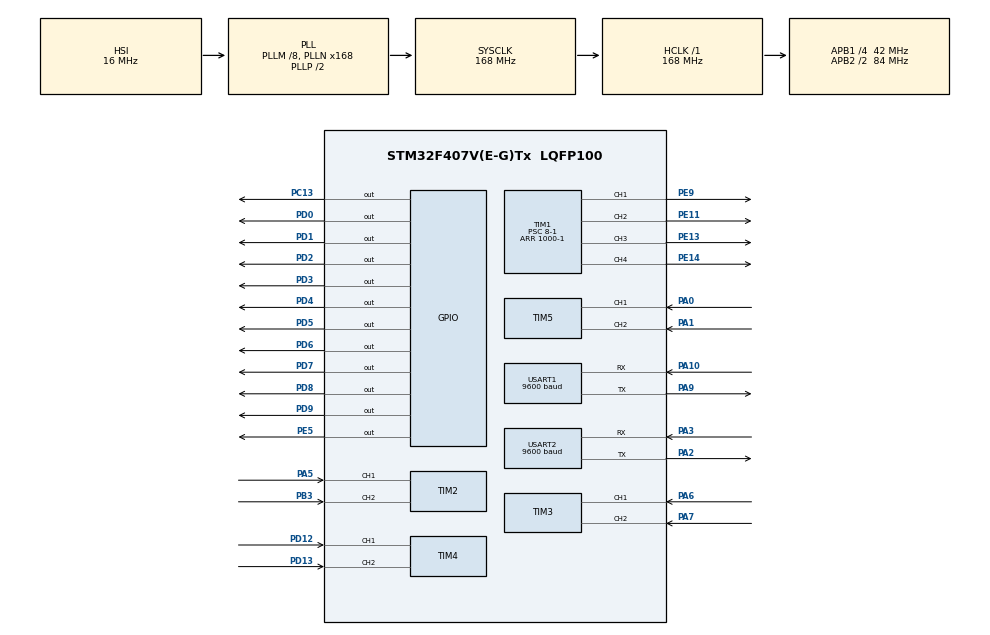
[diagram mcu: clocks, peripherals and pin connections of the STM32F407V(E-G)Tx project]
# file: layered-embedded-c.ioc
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Dma.Request0=USART1_RX
Dma.Request1=USART1_TX
Dma.Request2=USART2_RX
Dma.Request3=USART2_TX
Dma.USART1_RX.0.Direction=DMA_PERIPH_TO_MEMORY
Dma.USART1_RX.0.FIFOMode=DMA_FIFOMODE_DISABLE
Dma.USART1_RX.0.Instance=DMA2_Stream2
Dma.USART1_RX.0.MemDataAlignment=DMA_MDATAALIGN_BYTE
Dma.USART1_RX.0.MemInc=DMA_MINC_ENABLE
Dma.USART1_RX.0.Mode=DMA_CIRCULAR
Dma.USART1_RX.0.PeriphDataAlignment=DMA_PDATAALIGN_BYTE
Dma.USART1_RX.0.PeriphInc=DMA_PINC_DISABLE
Dma.USART1_RX.0.Priority=DMA_PRIORITY_LOW
Dma.USART1_TX.1.Direction=DMA_MEMORY_TO_PERIPH
Dma.USART1_TX.1.FIFOMode=DMA_FIFOMODE_DISABLE
Dma.USART1_TX.1.Instance=DMA2_Stream7
Dma.USART1_TX.1.MemDataAlignment=DMA_MDATAALIGN_BYTE
Dma.USART1_TX.1.MemInc=DMA_MINC_ENABLE
Dma.USART1_TX.1.Mode=DMA_NORMAL
Dma.USART1_TX.1.PeriphDataAlignment=DMA_PDATAALIGN_BYTE
Dma.USART1_TX.1.PeriphInc=DMA_PINC_DISABLE
Dma.USART1_TX.1.Priority=DMA_PRIORITY_LOW
Dma.USART2_RX.2.Direction=DMA_PERIPH_TO_MEMORY
Dma.USART2_RX.2.FIFOMode=DMA_FIFOMODE_DISABLE
Dma.USART2_RX.2.Instance=DMA1_Stream5
Dma.USART2_RX.2.MemDataAlignment=DMA_MDATAALIGN_BYTE
Dma.USART2_RX.2.MemInc=DMA_MINC_ENABLE
Dma.USART2_RX.2.Mode=DMA_CIRCULAR
Dma.USART2_RX.2.PeriphDataAlignment=DMA_PDATAALIGN_BYTE
Dma.USART2_RX.2.PeriphInc=DMA_PINC_DISABLE
Dma.USART2_RX.2.Priority=DMA_PRIORITY_LOW
Dma.USART2_TX.3.Direction=DMA_MEMORY_TO_PERIPH
Dma.USART2_TX.3.FIFOMode=DMA_FIFOMODE_DISABLE
Dma.USART2_TX.3.Instance=DMA1_Stream6
Dma.USART2_TX.3.MemDataAlignment=DMA_MDATAALIGN_BYTE
Dma.USART2_TX.3.MemInc=DMA_MINC_ENABLE
Dma.USART2_TX.3.Mode=DMA_NORMAL
Dma.USART2_TX.3.PeriphDataAlignment=DMA_PDATAALIGN_BYTE
Dma.USART2_TX.3.PeriphInc=DMA_PINC_DISABLE
Dma.USART2_TX.3.Priority=DMA_PRIORITY_LOW
FREERTOS.Tasks01=defaultTask,24,128,StartDefaultTask,Default,NULL,Dynamic,NULL,NULL;MonitorTask,8,512,RTOS_Monitor_StartTask,As weak,NULL,Dynamic,NULL,NULL;ControlTask,48,1024,RTOS_Control_StartTask,As weak,NULL,Dynamic,NULL,NULL;UARTTask,24,1024,RTOS_UART_StartTask,As weak,NULL,Dynamic,NULL,NULL
Mcu.Family=STM32F4
Mcu.Name=STM32F407V(E-G)Tx
Mcu.Package=LQFP100
NVIC.DMA1_Stream5_IRQn=true\:5\:0\:false\:false\:true\:true\:false\:true\:true
NVIC.DMA1_Stream6_IRQn=true\:5\:0\:false\:false\:true\:true\:false\:true\:true
NVIC.DMA2_Stream2_IRQn=true\:5\:0\:false\:false\:true\:true\:false\:true\:true
NVIC.DMA2_Stream7_IRQn=true\:5\:0\:false\:false\:true\:true\:false\:true\:true
NVIC.PriorityGroup=NVIC_PRIORITYGROUP_4
NVIC.TIM7_IRQn=true\:15\:0\:false\:false\:true\:false\:false\:true\:true
NVIC.TimeBase=TIM7_IRQn
NVIC.TimeBaseIP=TIM7
NVIC.USART1_IRQn=true\:5\:0\:false\:false\:true\:true\:true\:true\:true
PA0-WKUP.Signal=S_TIM5_CH1
PA1.Signal=S_TIM5_CH2
PA10.Mode=Asynchronous
PA10.Signal=USART1_RX
PA13.Mode=Serial_Wire
PA13.Signal=SYS_JTMS-SWDIO
PA14.Mode=Serial_Wire
PA14.Signal=SYS_JTCK-SWCLK
PA2.Mode=Asynchronous
PA2.Signal=USART2_TX
PA3.Mode=Asynchronous
PA3.Signal=USART2_RX
PA5.Signal=S_TIM2_CH1_ETR
PA6.Signal=S_TIM3_CH1
PA7.Signal=S_TIM3_CH2
PA9.Mode=Asynchronous
PA9.Signal=USART1_TX
PB3.Signal=S_TIM2_CH2
PC13-ANTI_TAMP.Signal=GPIO_Output
PD0.Signal=GPIO_Output
PD1.Signal=GPIO_Output
PD12.Signal=S_TIM4_CH1
PD13.Signal=S_TIM4_CH2
PD2.Signal=GPIO_Output
PD3.Signal=GPIO_Output
PD4.Signal=GPIO_Output
PD5.Signal=GPIO_Output
PD6.Signal=GPIO_Output
PD7.Signal=GPIO_Output
PD8.Signal=GPIO_Output
PD9.Signal=GPIO_Output
PE11.Signal=S_TIM1_CH2
PE13.Signal=S_TIM1_CH3
PE14.Signal=S_TIM1_CH4
PE5.Signal=GPIO_Output
PE9.Signal=S_TIM1_CH1
PH0-OSC_IN.Mode=HSE-External-Oscillator
PH0-OSC_IN.Signal=RCC_OSC_IN
PH1-OSC_OUT.Mode=HSE-External-Oscillator
PH1-OSC_OUT.Signal=RCC_OSC_OUT
ProjectManager.HeapSize=0x200
ProjectManager.StackSize=0x400
ProjectManager.TargetToolchain=CMake
RCC.48MHZClocksFreq_Value=84000000
RCC.AHBFreq_Value=168000000
RCC.APB1CLKDivider=RCC_HCLK_DIV4
RCC.APB1Freq_Value=42000000
RCC.APB1TimFreq_Value=84000000
RCC.APB2CLKDivider=RCC_HCLK_DIV2
RCC.APB2Freq_Value=84000000
RCC.APB2TimFreq_Value=168000000
RCC.CortexFreq_Value=168000000
RCC.HCLKFreq_Value=168000000
RCC.HSE_VALUE=25000000
RCC.HSI_VALUE=16000000
RCC.LSE_VALUE=32768
RCC.PLLM=8
RCC.PLLN=168
RCC.SYSCLKFreq_VALUE=168000000
RCC.SYSCLKSource=RCC_SYSCLKSOURCE_PLLCLK
RCC.VCOOutputFreq_Value=336000000
SH.S_TIM1_CH1.0=TIM1_CH1,PWM Generation1 CH1
SH.S_TIM1_CH2.0=TIM1_CH2,PWM Generation2 CH2
SH.S_TIM1_CH3.0=TIM1_CH3,PWM Generation3 CH3
SH.S_TIM1_CH4.0=TIM1_CH4,PWM Generation4 CH4
SH.S_TIM2_CH1_ETR.0=TIM2_CH1,Encoder_Interface
SH.S_TIM2_CH2.0=TIM2_CH2,Encoder_Interface
SH.S_TIM3_CH1.0=TIM3_CH1,Encoder_Interface
SH.S_TIM3_CH2.0=TIM3_CH2,Encoder_Interface
SH.S_TIM4_CH1.0=TIM4_CH1,Encoder_Interface
SH.S_TIM4_CH2.0=TIM4_CH2,Encoder_Interface
SH.S_TIM5_CH1.0=TIM5_CH1,Encoder_Interface
SH.S_TIM5_CH2.0=TIM5_CH2,Encoder_Interface
TIM1.Channel-PWM\ Generation1\ CH1=TIM_CHANNEL_1
TIM1.Channel-PWM\ Generation2\ CH2=TIM_CHANNEL_2
TIM1.Channel-PWM\ Generation3\ CH3=TIM_CHANNEL_3
TIM1.Channel-PWM\ Generation4\ CH4=TIM_CHANNEL_4
TIM1.Period=1000-1
TIM1.Prescaler=8-1
TIM2.EncoderMode=TIM_ENCODERMODE_TI12
TIM2.IC1Filter=15
TIM2.IC2Filter=15
TIM3.EncoderMode=TIM_ENCODERMODE_TI12
TIM3.IC1Filter=15
TIM3.IC2Filter=15
TIM4.EncoderMode=TIM_ENCODERMODE_TI12
TIM4.IC1Filter=15
TIM4.IC2Filter=15
TIM5.EncoderMode=TIM_ENCODERMODE_TI12
TIM5.IC1Filter=15
TIM5.IC2Filter=15
USART1.BaudRate=9600
USART1.VirtualMode=VM_ASYNC
USART2.BaudRate=9600
USART2.VirtualMode=VM_ASYNC
VP_FREERTOS_VS_CMSIS_V2.Mode=CMSIS_V2
VP_SYS_VS_tim7.Mode=TIM7
VP_TIM1_VS_ClockSourceINT.Mode=Internal
board=custom

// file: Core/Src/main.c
/* USER CODE BEGIN Header */
/**
  ******************************************************************************
  * @file           : main.c
  * @brief          : Main program body
  ******************************************************************************
  * @attention
  *
  * Copyright (c) 2026 STMicroelectronics.
  * All rights reserved.
  *
  * This software is licensed under terms that can be found in the LICENSE file
  * in the root directory of this software component.
  * If no LICENSE file comes with this software, it is provided AS-IS.
  *
  ******************************************************************************
  */
/* USER CODE END Header */
#include "main.h"
#include "cmsis_os.h"
#include "dma.h"
#include "tim.h"
#include "usart.h"
#include "gpio.h"

/* USER CODE BEGIN Includes */
#include "system_delay.h"
/* USER CODE END Includes */

void SystemClock_Config(void);
void MX_FREERTOS_Init(void);

int main(void)
{

  /* MCU Configuration--------------------------------------------------------*/

  /* Reset of all peripherals, Initializes the Flash interface and the Systick. */
  HAL_Init();

  /* Configure the system clock */
  SystemClock_Config();

  /* Initialize all configured peripherals */
  MX_GPIO_Init();
  MX_DMA_Init();
  MX_TIM1_Init();
  MX_USART1_UART_Init();
  MX_TIM2_Init();
  MX_TIM3_Init();
  MX_TIM4_Init();
  MX_TIM5_Init();
  MX_USART2_UART_Init();
  /* USER CODE BEGIN 2 */
  Sys_Delay_Init();
  /* USER CODE END 2 */

  /* Init scheduler */
  osKernelInitialize();  /* Call init function for freertos objects (in cmsis_os2.c) */
  MX_FREERTOS_Init();

  /* Start scheduler */
  osKernelStart();

  /* We should never get here as control is now taken by the scheduler */

  /* Infinite loop */
  while (1)
  {

  }
}

void SystemClock_Config(void)
{
  RCC_OscInitTypeDef RCC_OscInitStruct = {0};
  RCC_ClkInitTypeDef RCC_ClkInitStruct = {0};

  /** Configure the main internal regulator output voltage
  */
  __HAL_RCC_PWR_CLK_ENABLE();
  __HAL_PWR_VOLTAGESCALING_CONFIG(PWR_REGULATOR_VOLTAGE_SCALE1);

  /** Initializes the RCC Oscillators according to the specified parameters
  * in the RCC_OscInitTypeDef structure.
  */
  RCC_OscInitStruct.OscillatorType = RCC_OSCILLATORTYPE_HSI;
  RCC_OscInitStruct.HSIState = RCC_HSI_ON;
  RCC_OscInitStruct.HSICalibrationValue = RCC_HSICALIBRATION_DEFAULT;
  RCC_OscInitStruct.PLL.PLLState = RCC_PLL_ON;
  RCC_OscInitStruct.PLL.PLLSource = RCC_PLLSOURCE_HSI;
  RCC_OscInitStruct.PLL.PLLM = 8;
  RCC_OscInitStruct.PLL.PLLN = 168;
  RCC_OscInitStruct.PLL.PLLP = RCC_PLLP_DIV2;
  RCC_OscInitStruct.PLL.PLLQ = 4;
  if (HAL_RCC_OscConfig(&RCC_OscInitStruct) != HAL_OK)
  {
    Error_Handler();
  }

  /** Initializes the CPU, AHB and APB buses clocks
  */
  RCC_ClkInitStruct.ClockType = RCC_CLOCKTYPE_HCLK|RCC_CLOCKTYPE_SYSCLK
                              |RCC_CLOCKTYPE_PCLK1|RCC_CLOCKTYPE_PCLK2;
  RCC_ClkInitStruct.SYSCLKSource = RCC_SYSCLKSOURCE_PLLCLK;
  RCC_ClkInitStruct.AHBCLKDivider = RCC_SYSCLK_DIV1;
  RCC_ClkInitStruct.APB1CLKDivider = RCC_HCLK_DIV4;
  RCC_ClkInitStruct.APB2CLKDivider = RCC_HCLK_DIV2;

  if (HAL_RCC_ClockConfig(&RCC_ClkInitStruct, FLASH_LATENCY_5) != HAL_OK)
  {
    Error_Handler();
  }
}

void HAL_TIM_PeriodElapsedCallback(TIM_HandleTypeDef *htim)
{
  if (htim->Instance == TIM7)
  {
    HAL_IncTick();
  }
}

void Error_Handler(void)
{
  __disable_irq();
  while (1)
  {
  }
}

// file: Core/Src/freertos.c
/* USER CODE BEGIN Header */
/**
  ******************************************************************************
  * File Name          : freertos.c
  * Description        : Code for freertos applications
  ******************************************************************************
  * @attention
  *
  * Copyright (c) 2026 STMicroelectronics.
  * All rights reserved.
  *
  * This software is licensed under terms that can be found in the LICENSE file
  * in the root directory of this software component.
  * If no LICENSE file comes with this software, it is provided AS-IS.
  *
  ******************************************************************************
  */
/* USER CODE END Header */

#include "FreeRTOS.h"
#include "task.h"
#include "main.h"
#include "cmsis_os.h"

/* Definitions for defaultTask */
osThreadId_t defaultTaskHandle;
const osThreadAttr_t defaultTask_attributes = {
  .name = "defaultTask",
  .stack_size = 128 * 4,
  .priority = (osPriority_t) osPriorityNormal,
};
/* Definitions for MonitorTask */
osThreadId_t MonitorTaskHandle;
const osThreadAttr_t MonitorTask_attributes = {
  .name = "MonitorTask",
  .stack_size = 512 * 4,
  .priority = (osPriority_t) osPriorityLow,
};
/* Definitions for ControlTask */
osThreadId_t ControlTaskHandle;
const osThreadAttr_t ControlTask_attributes = {
  .name = "ControlTask",
  .stack_size = 1024 * 4,
  .priority = (osPriority_t) osPriorityRealtime,
};
/* Definitions for UARTTask */
osThreadId_t UARTTaskHandle;
const osThreadAttr_t UARTTask_attributes = {
  .name = "UARTTask",
  .stack_size = 1024 * 4,
  .priority = (osPriority_t) osPriorityNormal,
};

void StartDefaultTask(void *argument);
void RTOS_Monitor_StartTask(void *argument);
void RTOS_Control_StartTask(void *argument);
void RTOS_UART_StartTask(void *argument);

void MX_FREERTOS_Init(void); /* (MISRA C 2004 rule 8.1) */

void MX_FREERTOS_Init(void) {

  /* Create the thread(s) */
  /* creation of defaultTask */
  defaultTaskHandle = osThreadNew(StartDefaultTask, NULL, &defaultTask_attributes);

  /* creation of MonitorTask */
  MonitorTaskHandle = osThreadNew(RTOS_Monitor_StartTask, NULL, &MonitorTask_attributes);

  /* creation of ControlTask */
  ControlTaskHandle = osThreadNew(RTOS_Control_StartTask, NULL, &ControlTask_attributes);

  /* creation of UARTTask */
  UARTTaskHandle = osThreadNew(RTOS_UART_StartTask, NULL, &UARTTask_attributes);

}

void StartDefaultTask(void *argument)
{
  /* USER CODE BEGIN StartDefaultTask */
  (void)argument;
  /* Infinite loop */
  for(;;)
  {
    osDelay(1);
  }
  /* USER CODE END StartDefaultTask */
}

__weak void RTOS_Monitor_StartTask(void *argument)
{
  /* USER CODE BEGIN RTOS_Monitor_StartTask */
  (void)argument;
  /* Infinite loop */
  for(;;)
  {
    osDelay(1);
  }
  /* USER CODE END RTOS_Monitor_StartTask */
}

__weak void RTOS_Control_StartTask(void *argument)
{
  /* USER CODE BEGIN RTOS_Control_StartTask */
  (void)argument;
  /* Infinite loop */
  for(;;)
  {
    osDelay(1);
  }
  /* USER CODE END RTOS_Control_StartTask */
}

__weak void RTOS_UART_StartTask(void *argument)
{
  /* USER CODE BEGIN RTOS_UART_StartTask */
  (void)argument;
  /* Infinite loop */
  for(;;)
  {
    osDelay(1);
  }
  /* USER CODE END RTOS_UART_StartTask */
}
